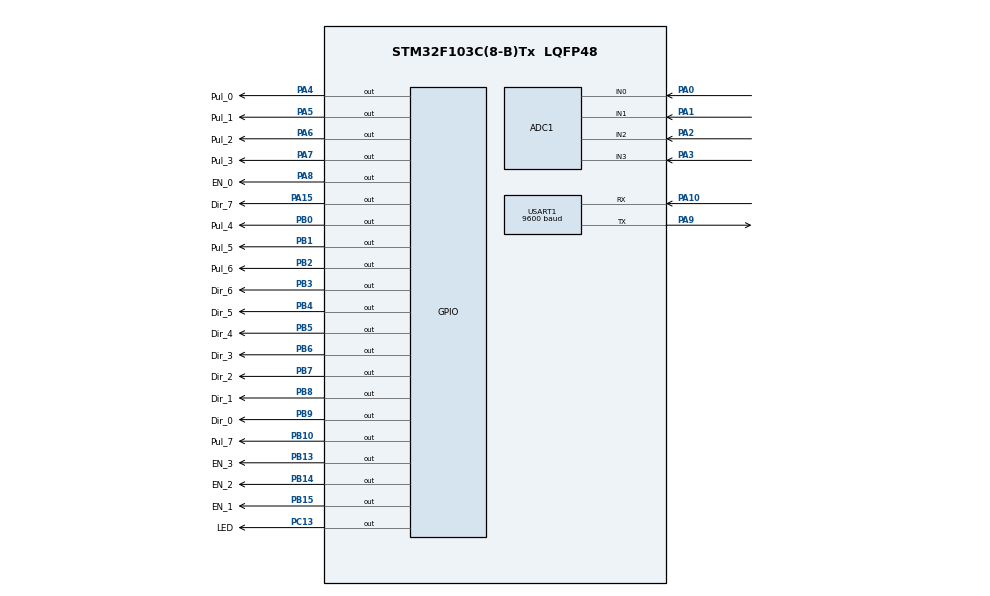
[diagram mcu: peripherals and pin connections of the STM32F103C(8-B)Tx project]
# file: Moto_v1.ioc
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ADC1.Channel-0\#ChannelRegularConversion=ADC_CHANNEL_0
ADC1.Channel-1\#ChannelRegularConversion=ADC_CHANNEL_1
ADC1.Channel-2\#ChannelRegularConversion=ADC_CHANNEL_2
ADC1.Channel-3\#ChannelRegularConversion=ADC_CHANNEL_3
ADC1.ContinuousConvMode=ENABLE
ADC1.NbrOfConversion=4
ADC1.NbrOfConversionFlag=1
ADC1.Rank-0\#ChannelRegularConversion=1
ADC1.Rank-1\#ChannelRegularConversion=2
ADC1.Rank-2\#ChannelRegularConversion=3
ADC1.Rank-3\#ChannelRegularConversion=4
ADC1.SamplingTime-0\#ChannelRegularConversion=ADC_SAMPLETIME_55CYCLES_5
ADC1.SamplingTime-1\#ChannelRegularConversion=ADC_SAMPLETIME_55CYCLES_5
ADC1.SamplingTime-2\#ChannelRegularConversion=ADC_SAMPLETIME_55CYCLES_5
ADC1.SamplingTime-3\#ChannelRegularConversion=ADC_SAMPLETIME_55CYCLES_5
ADC1.master=1
Dma.ADC1.0.Direction=DMA_PERIPH_TO_MEMORY
Dma.ADC1.0.Instance=DMA1_Channel1
Dma.ADC1.0.MemDataAlignment=DMA_MDATAALIGN_HALFWORD
Dma.ADC1.0.MemInc=DMA_MINC_ENABLE
Dma.ADC1.0.Mode=DMA_CIRCULAR
Dma.ADC1.0.PeriphDataAlignment=DMA_PDATAALIGN_HALFWORD
Dma.ADC1.0.PeriphInc=DMA_PINC_DISABLE
Dma.ADC1.0.Priority=DMA_PRIORITY_LOW
Dma.Request0=ADC1
Mcu.Family=STM32F1
Mcu.Name=STM32F103C(8-B)Tx
Mcu.Package=LQFP48
NVIC.ADC1_2_IRQn=true\:0\:0\:false\:false\:true\:true\:true
NVIC.DMA1_Channel1_IRQn=true\:0\:0\:false\:false\:true\:false\:true
NVIC.PriorityGroup=NVIC_PRIORITYGROUP_4
NVIC.TIM2_IRQn=true\:0\:0\:false\:false\:true\:true\:true
NVIC.USART1_IRQn=true\:0\:0\:false\:false\:true\:true\:true
PA0-WKUP.Signal=ADCx_IN0
PA1.Signal=ADCx_IN1
PA10.Mode=Asynchronous
PA10.Signal=USART1_RX
PA13.Mode=Serial_Wire
PA13.Signal=SYS_JTMS-SWDIO
PA14.Mode=Serial_Wire
PA14.Signal=SYS_JTCK-SWCLK
PA15.GPIO_Label=Dir_7
PA15.Signal=GPIO_Output
PA2.Signal=ADCx_IN2
PA3.Signal=ADCx_IN3
PA4.GPIO_Label=Pul_0
PA4.Signal=GPIO_Output
PA5.GPIO_Label=Pul_1
PA5.Signal=GPIO_Output
PA6.GPIO_Label=Pul_2
PA6.Signal=GPIO_Output
PA7.GPIO_Label=Pul_3
PA7.Signal=GPIO_Output
PA8.GPIO_Label=EN_0
PA8.Signal=GPIO_Output
PA9.Mode=Asynchronous
PA9.Signal=USART1_TX
PB0.GPIO_Label=Pul_4
PB0.Signal=GPIO_Output
PB1.GPIO_Label=Pul_5
PB1.Signal=GPIO_Output
PB10.GPIO_Label=Pul_7
PB10.Signal=GPIO_Output
PB13.GPIO_Label=EN_3
PB13.Signal=GPIO_Output
PB14.GPIO_Label=EN_2
PB14.Signal=GPIO_Output
PB15.GPIO_Label=EN_1
PB15.Signal=GPIO_Output
PB2.GPIO_Label=Pul_6
PB2.Signal=GPIO_Output
PB3.GPIO_Label=Dir_6
PB3.Signal=GPIO_Output
PB4.GPIO_Label=Dir_5
PB4.Signal=GPIO_Output
PB5.GPIO_Label=Dir_4
PB5.Signal=GPIO_Output
PB6.GPIO_Label=Dir_3
PB6.Signal=GPIO_Output
PB7.GPIO_Label=Dir_2
PB7.Signal=GPIO_Output
PB8.GPIO_Label=Dir_1
PB8.Signal=GPIO_Output
PB9.GPIO_Label=Dir_0
PB9.Signal=GPIO_Output
PC13-TAMPER-RTC.GPIO_Label=LED
PC13-TAMPER-RTC.Signal=GPIO_Output
PD0-OSC_IN.Mode=HSE-External-Oscillator
PD0-OSC_IN.Signal=RCC_OSC_IN
PD1-OSC_OUT.Mode=HSE-External-Oscillator
PD1-OSC_OUT.Signal=RCC_OSC_OUT
ProjectManager.HeapSize=0x200
ProjectManager.StackSize=0x400
ProjectManager.TargetToolchain=MDK-ARM V5
RCC.APB1Freq_Value=8000000
RCC.APB2Freq_Value=8000000
SH.ADCx_IN0.0=ADC1_IN0,IN0
SH.ADCx_IN1.0=ADC1_IN1,IN1
SH.ADCx_IN2.0=ADC1_IN2,IN2
SH.ADCx_IN3.0=ADC1_IN3,IN3
TIM2.Period=100-1
TIM2.Prescaler=72-1
USART1.BaudRate=9600
USART1.VirtualMode=VM_ASYNC
VP_TIM2_VS_ClockSourceINT.Mode=Internal
board=custom

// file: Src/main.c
/* USER CODE BEGIN Header */
/**
  ******************************************************************************
  * @file           : main.c
  * @brief          : Main program body
  ******************************************************************************
  * @attention
  *
  * <h2><center>&copy; Copyright (c) 2019 STMicroelectronics.
  * All rights reserved.</center></h2>
  *
  * This software component is licensed by ST under BSD 3-Clause license,
  * the "License"; You may not use this file except in compliance with the
  * License. You may obtain a copy of the License at:
  *                        opensource.org/licenses/BSD-3-Clause
  *
  ******************************************************************************
  */
/* USER CODE END Header */

#include "main.h"
#include "adc.h"
#include "dma.h"
#include "tim.h"
#include "usart.h"
#include "gpio.h"

/* USER CODE BEGIN Includes */
#include"control.h"
/* USER CODE END Includes */

/* USER CODE BEGIN PV */
extern uint8_t Res;  //串口接收缓存
extern struct MotoTypedef Motor[8]; //八个电机，0-3是俯仰角，4-7是偏航角
extern uint32_t ADC_Buffer[60];  //adc缓存区
/* USER CODE END PV */

void SystemClock_Config(void);

int main(void)
{

  /* MCU Configuration--------------------------------------------------------*/

  /* Reset of all peripherals, Initializes the Flash interface and the Systick. */
  HAL_Init();

  /* Configure the system clock */
  SystemClock_Config();

  /* Initialize all configured peripherals */
  MX_GPIO_Init();
  MX_DMA_Init();
  MX_ADC1_Init();
  MX_TIM2_Init();
  MX_USART1_UART_Init();

  /* USER CODE BEGIN 2 */
  HAL_UART_Receive_IT(&huart1,&Res,1);  //打开串口
	HAL_ADCEx_Calibration_Start(&hadc1);	 //adc校准
  HAL_ADC_Start_DMA(&hadc1,ADC_Buffer,100);  //打开adc
	MotorConfig();     //电机初始化，绑定电机
	HAL_TIM_Base_Start_IT(&htim2);

	AutoWorkNow(4,&Motor[1],&Motor[2],&Motor[0],&Motor[3]);

  /* USER CODE END 2 */

  /* Infinite loop */
  while (1)
  {

    /* USER CODE BEGIN 3 */
		Main_Round();  //主循环
	//	HAL_Delay(100);
  }
  /* USER CODE END 3 */
}

void SystemClock_Config(void)
{
  RCC_OscInitTypeDef RCC_OscInitStruct = {0};
  RCC_ClkInitTypeDef RCC_ClkInitStruct = {0};
  RCC_PeriphCLKInitTypeDef PeriphClkInit = {0};

  /** Initializes the CPU, AHB and APB busses clocks
  */
  RCC_OscInitStruct.OscillatorType = RCC_OSCILLATORTYPE_HSI;
  RCC_OscInitStruct.HSIState = RCC_HSI_ON;
  RCC_OscInitStruct.HSICalibrationValue = RCC_HSICALIBRATION_DEFAULT;
  RCC_OscInitStruct.PLL.PLLState = RCC_PLL_NONE;
  if (HAL_RCC_OscConfig(&RCC_OscInitStruct) != HAL_OK)
  {
    Error_Handler();
  }
  /** Initializes the CPU, AHB and APB busses clocks
  */
  RCC_ClkInitStruct.ClockType = RCC_CLOCKTYPE_HCLK|RCC_CLOCKTYPE_SYSCLK
                              |RCC_CLOCKTYPE_PCLK1|RCC_CLOCKTYPE_PCLK2;
  RCC_ClkInitStruct.SYSCLKSource = RCC_SYSCLKSOURCE_HSI;
  RCC_ClkInitStruct.AHBCLKDivider = RCC_SYSCLK_DIV1;
  RCC_ClkInitStruct.APB1CLKDivider = RCC_HCLK_DIV1;
  RCC_ClkInitStruct.APB2CLKDivider = RCC_HCLK_DIV1;

  if (HAL_RCC_ClockConfig(&RCC_ClkInitStruct, FLASH_LATENCY_0) != HAL_OK)
  {
    Error_Handler();
  }
  PeriphClkInit.PeriphClockSelection = RCC_PERIPHCLK_ADC;
  PeriphClkInit.AdcClockSelection = RCC_ADCPCLK2_DIV2;
  if (HAL_RCCEx_PeriphCLKConfig(&PeriphClkInit) != HAL_OK)
  {
    Error_Handler();
  }
}

void Error_Handler(void)
{
}

/************************ (C) COPYRIGHT STMicroelectronics *****END OF FILE****/
